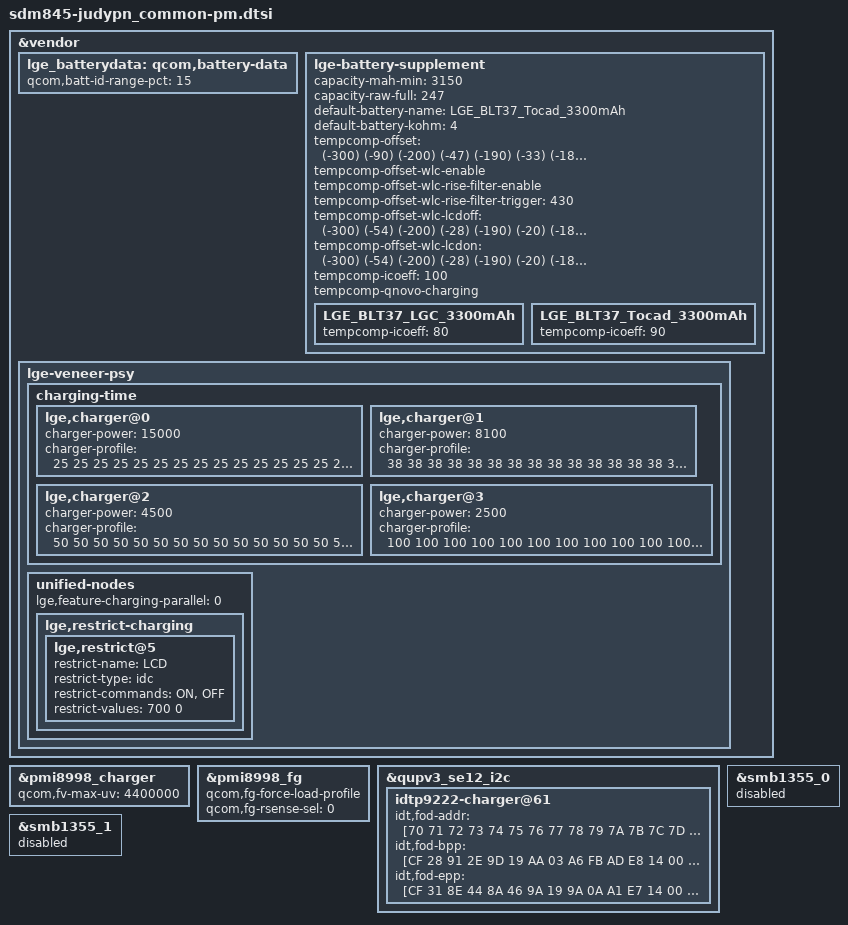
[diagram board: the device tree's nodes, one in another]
/* Copyright (c) 2017, The Linux Foundation. All rights reserved.
 *
 * This program is free software; you can redistribute it and/or modify
 * it under the terms of the GNU General Public License version 2 and
 * only version 2 as published by the Free Software Foundation.
 *
 * This program is distributed in the hope that it will be useful,
 * but WITHOUT ANY WARRANTY; without even the implied warranty of
 * MERCHANTABILITY or FITNESS FOR A PARTICULAR PURPOSE.  See the
 * GNU General Public License for more details.
 */

#include "../sdm845-judy_common/sdm845-judy_common-pm.dtsi"

&vendor {
	lge_batterydata: qcom,battery-data {
		qcom,batt-id-range-pct = <15>;
		#include "../../sdm845-battery/LGE_BLT37_LGC_3300mAh.dtsi"
		#include "../../sdm845-battery/LGE_BLT37_Tocad_3300mAh.dtsi"
	};

	lge-battery-supplement {
		capacity-mah-min = <3150>;
		capacity-raw-full = <247>;

		default-battery-name = "LGE_BLT37_Tocad_3300mAh";
		default-battery-kohm = <4>;

		/* format : (temp index) (temp delta) */
		tempcomp-offset = <
			(-300) (-90)
			(-200) (-47)
			(-190) (-33)
			(-180) (-20)
			(-170) (-14)
			(-160) ( -7)
			(-150)    0
			(-100)    8
			(-50)     9
			0         8
			50        6
			100       1
			150    ( -4)
			200    ( -9)
			250    (-12)
			300    (-21)
			350    (-26)
			400    (-31)
			450    (-34)
			500    (-32)
			550    (-30)
			600    (-24)
			700    (-11)
			800    (-11)
			900    (-11)
		>;

		tempcomp-offset-wlc-enable;
		tempcomp-offset-wlc-rise-filter-enable;
		tempcomp-offset-wlc-rise-filter-trigger = <430>;
		tempcomp-offset-wlc-lcdoff = <
			(-300) (-54)
			(-200) (-28)
			(-190) (-20)
			(-180) (-12)
			(-170) ( -8)
			(-160) ( -4)
			(-150)    0
			(-100)    8
			(-50)     9
			0         8
			50        6
			100       1
			150    ( -4)
			200    ( -9)
			250    (-12)
			300    (-21)
			350    (-26)
			400    (-31)
			450    (-34)
			500    (-32)
			550    (-30)
			600    (-24)
			700    (-11)
			800    (-11)
			900    (-11)
		>;

		tempcomp-offset-wlc-lcdon = <
			(-300) (-54)
			(-200) (-28)
			(-190) (-20)
			(-180) (-12)
			(-170) ( -8)
			(-160) ( -4)
			(-150)    0
			(-100)    8
			(-50)     9
			0         8
			50        6
			100       1
			150    ( -4)
			200    ( -9)
			250    (-12)
			300    (-21)
			350    (-30)
			400    (-40)
			450    (-50)
			500    (-70)
			550    (-30)
			600    (-24)
			700    (-11)
			800    (-11)
			900    (-11)
		>;
		tempcomp-icoeff = <100>;
		tempcomp-qnovo-charging;

		/* overriding by battery type */
		LGE_BLT37_LGC_3300mAh {
			tempcomp-icoeff = <80>;
		};
		LGE_BLT37_Tocad_3300mAh {
			tempcomp-icoeff = <90>;
		};
	};

	lge-veneer-psy {
		charging-time {
			#address-cells = <1>;
			#size-cells = <0>;

			lge,charger@0 {		//  fast charger: 9000mV * 1660mA or 5000mV * 3000mA
				charger-power = <15000>;
				charger-profile = <
					 25  25  25  25  25  25  25  25  25  25  25  25  25  25  25  25
					 25  25  25  25  25  25  25  25  25  25  25  25  25  25  25  25
					 25  25  25  25  25  25  25  25  25  25  25  25  25  25  25  25
					 25  25  25  25  25  25  25  25  25  25  25  25  25  25  25  25
					 25  25  25  25  25  25  25  25  25  25  25  25  25  25  25  25
					 25  25  25  25  25  25  25  25  25  25  25  25  25  25  25  25
					 25  25  25  25  25  25  25  25  25  25  25  25  25  25  25  25
					 25  25  25  25  25  25  25  25  25  25  25  25  25  25  25  25
					 25  25  25  25  25  25  25  25  25  25  25  25  25  25  25  25
					 25  25  25  25  25  25  25  25  25  25  25  25  25  25  25  25
					 25  25  25  25  25  25  25  25  25  25  25  25  25  25  25  25
					 25  25  25  25  25  25  25  25  25  25  25  25  25  25  25  25
					 25  25  25  25  25  25  25  25  25  25  25  25  25  25  25  25
					 25  25  25  25  25  25  25  25  25  25  25  25  25  25  25  25
					 25  25  25  25  25  25  25  25  25  25  25  25  25  25  25  25
					 25  25  25  25  25  25  25  25  25  25  25  25  25  25  25  25
				>;
			};
			lge,charger@1 {		// EPP wireless charger: 9000mV * 900mA = 8.1W
				charger-power = <8100>;
				charger-profile = <
					 38  38  38  38  38  38  38  38  38  38  38  38  38  38  38  38
					 38  38  38  38  38  38  38  38  38  38  38  38  38  38  38  38
					 38  38  38  38  38  38  38  38  38  38  38  38  38  38  38  38
					 38  38  38  38  38  38  38  38  38  38  38  38  38  38  38  38
					 38  38  38  38  38  38  38  38  38  38  38  38  38  38  38  38
					 38  38  38  38  38  38  38  38  38  38  38  38  38  38  38  38
					 38  38  38  38  38  38  38  38  38  38  38  38  38  38  38  38
					 38  38  38  38  38  38  38  38  38  38  38  38  38  38  38  38
					 38  38  38  38  38  38  38  38  38  38  38  38  38  38  38  38
					 38  38  38  38  38  38  38  38  38  38  38  38  38  38  38  38
					 38  38  38  38  38  38  38  38  38  38  38  38  38  38  38  38
					 38  38  38  38  38  38  38  38  38  38  38  38  38  38  38  38
					 38  38  38  38  38  38  38  38  38  38  38  38  38  38  38  38
					 38  38  38  38  38  38  38  38  38  38  38  38  38  38  38  38
					 38  38  38  38  38  38  38  38  38  38  38  38  38  38  38  38
					 38  38  38  38  38  38  38  38  38  38  38  38  38  38  38  38
				>;
			};
			lge,charger@2 {		// BPP wireless charger: 5000mV * 900mA = 4.5W
				charger-power = <4500>;
				charger-profile = <
					 50  50  50  50  50  50  50  50  50  50  50  50  50  50  50  50
					 50  50  50  50  50  50  50  50  50  50  50  50  50  50  50  50
					 50  50  50  50  50  50  50  50  50  50  50  50  50  50  50  50
					 50  50  50  50  50  50  50  50  50  50  50  50  50  50  50  50
					 50  50  50  50  50  50  50  50  50  50  50  50  50  50  50  50
					 50  50  50  50  50  50  50  50  50  50  50  50  50  50  50  50
					 50  50  50  50  50  50  50  50  50  50  50  50  50  50  50  50
					 50  50  50  50  50  50  50  50  50  50  50  50  50  50  50  50
					 50  50  50  50  50  50  50  50  50  50  50  50  50  50  50  50
					 50  50  50  50  50  50  50  50  50  50  50  50  50  50  50  50
					 50  50  50  50  50  50  50  50  50  50  50  50  50  50  50  50
					 50  50  50  50  50  50  50  50  50  50  50  50  50  50  50  50
					 50  50  50  50  50  50  50  50  50  50  50  50  50  50  50  50
					 50  50  50  50  50  50  50  50  50  50  50  50  50  50  50  50
					 50  50  50  50  50  50  50  50  50  50  50  50  50  50  50  50
					 50  50  50  50  50  50  50  50  50  50  50  50  50  50  50  50
				>;
			};
			lge,charger@3 {		// SDP: 5000mV * 500mA = 2.5W
				charger-power = <2500>;
				charger-profile = <
					100 100 100 100 100 100 100 100 100 100 100 100 100 100 100 100
					100 100 100 100 100 100 100 100 100 100 100 100 100 100 100 100
					100 100 100 100 100 100 100 100 100 100 100 100 100 100 100 100
					100 100 100 100 100 100 100 100 100 100 100 100 100 100 100 100
					100 100 100 100 100 100 100 100 100 100 100 100 100 100 100 100
					100 100 100 100 100 100 100 100 100 100 100 100 100 100 100 100
					100 100 100 100 100 100 100 100 100 100 100 100 100 100 100 100
					100 100 100 100 100 100 100 100 100 100 100 100 100 100 100 100
					100 100 100 100 100 100 100 100 100 100 100 100 100 100 100 100
					100 100 100 100 100 100 100 100 100 100 100 100 100 100 100 100
					100 100 100 100 100 100 100 100 100 100 100 100 100 100 100 100
					100 100 100 100 100 100 100 100 100 100 100 100 100 100 100 100
					100 100 100 100 100 100 100 100 100 100 100 100 100 100 100 100
					100 100 100 100 100 100 100 100 100 100 100 100 100 100 100 100
					100 100 100 100 100 100 100 100 100 100 100 100 100 100 100 100
					100 100 100 100 100 100 100 100 100 100 100 100 100 100 100 100
				>;
			};
		};

		unified-nodes {
			lge,feature-charging-parallel = <0>;

			lge,restrict-charging {
				lge,restrict@5 {
					restrict-name = "LCD";
					restrict-type = "idc";
					restrict-commands = "ON", "OFF";
					restrict-values = < 700      0>;
				};
			};
		};
	};
};

&pmi8998_charger {
	qcom,fv-max-uv = <4400000>;
};

&pmi8998_fg {
	qcom,fg-force-load-profile;
	qcom,fg-rsense-sel = <0>;
};

&qupv3_se12_i2c {
	idtp9222-charger@61 {
		// FOD parameters
		idt,fod-addr = [70 71 72 73 74 75 76 77 78 79 7A 7B 7C 7D 7E 7F];
		idt,fod-bpp  = [CF 28 91 2E 9D 19 AA 03 A6 FB AD E8 14 00 00 00];
		idt,fod-epp  = [CF 31 8E 44 8A 46 9A 19 9A 0A A1 E7 14 00 64 32];
	};
};

&smb1355_0 {
	status = "disabled";
};

&smb1355_1 {
	status = "disabled";
};
